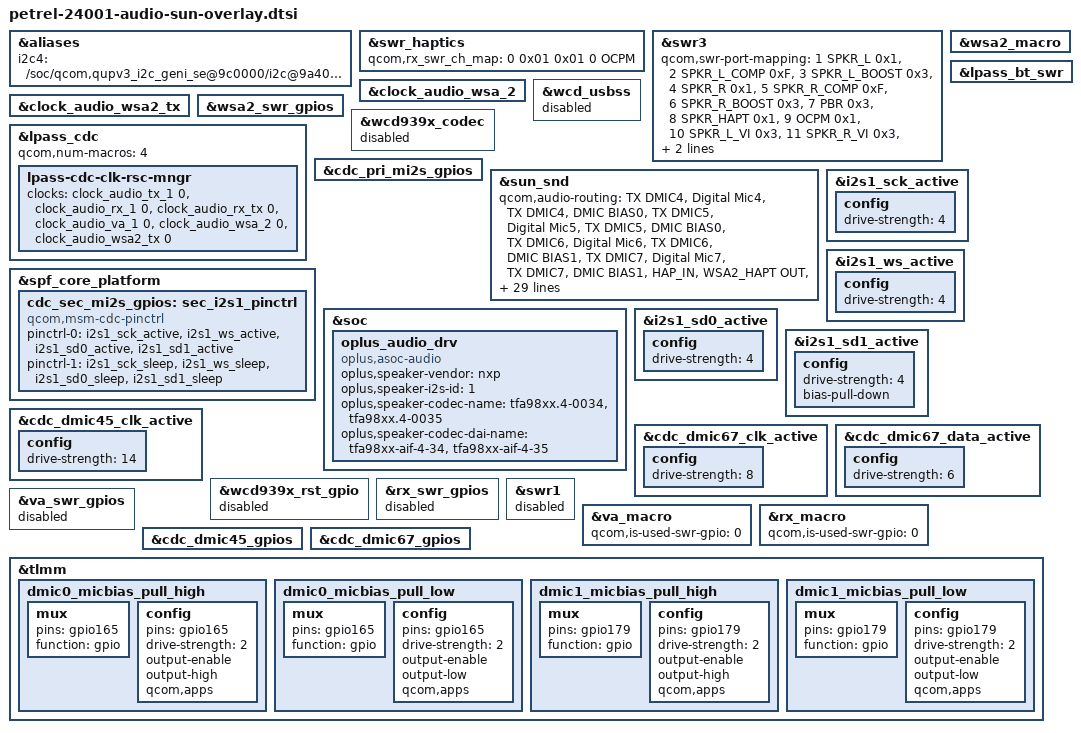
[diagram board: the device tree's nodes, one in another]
#include <dt-bindings/regulator/qcom,rpmh-regulator-levels.h>

&aliases {
	i2c4 = "/soc/qcom,qupv3_i2c_geni_se@9c0000/i2c@9a4000";
};

&swr_haptics {
	status = "ok";
	qcom,rx_swr_ch_map = <0 0x01 0x01 0 OCPM>;
};

&swr3 {
	qcom,swr-port-mapping = <1 SPKR_L 0x1>,
		<2 SPKR_L_COMP 0xF>, <3 SPKR_L_BOOST 0x3>,
		<4 SPKR_R 0x1>, <5 SPKR_R_COMP 0xF>,
		<6 SPKR_R_BOOST 0x3>, <7 PBR 0x3>,
		<8 SPKR_HAPT 0x1>, <9 OCPM 0x1>, // Change from <9 OCPM 0x3> to <9 OCPM 0x1>
		<10 SPKR_L_VI 0x3>, <11 SPKR_R_VI 0x3>,
		<12 SPKR_IPCM 0x3>, <13 CPS 0x3>;
};

&clock_audio_wsa_2 {
	status = "ok";
};

&clock_audio_wsa2_tx {
	status = "ok";
};

&wsa2_swr_gpios {
	status = "ok";
};

&swr3 {
	qcom,swr-num-dev = <1>; // only haptics connected
};

&wsa2_macro {
	status = "ok";
};

&lpass_cdc {
	qcom,num-macros = <4>;
	lpass-cdc-clk-rsc-mngr {
		clock-names = "tx_core_clk", "rx_core_clk", "rx_tx_core_clk", "va_core_clk",
		"wsa2_core_clk", "wsa2_tx_core_clk";
		clocks = <&clock_audio_tx_1 0>, <&clock_audio_rx_1 0>,
			<&clock_audio_rx_tx 0>, <&clock_audio_va_1 0>,
			<&clock_audio_wsa_2 0>, <&clock_audio_wsa2_tx 0>;
	};
};

&lpass_bt_swr {
	status = "ok";
};

&wcd_usbss {
	status = "disabled";
};

&wcd939x_codec {
	status = "disabled";
};

&cdc_pri_mi2s_gpios {
	status = "ok";
};

&sun_snd {
	qcom,audio-routing =
		"TX DMIC4", "Digital Mic4",
		"TX DMIC4", "DMIC BIAS0",
		"TX DMIC5", "Digital Mic5",
		"TX DMIC5", "DMIC BIAS0",
		"TX DMIC6", "Digital Mic6",
		"TX DMIC6", "DMIC BIAS1",
		"TX DMIC7", "Digital Mic7",
		"TX DMIC7", "DMIC BIAS1",
		"HAP_IN", "WSA2_HAPT OUT", // haptics connect to wsa2
		"RX_TX DEC0_INP", "TX DEC0 MUX",
		"RX_TX DEC1_INP", "TX DEC1 MUX",
		"RX_TX DEC2_INP", "TX DEC2 MUX",
		"RX_TX DEC3_INP", "TX DEC3 MUX",
		"VA SWR_INPUT", "VA_SWR_CLK",
		"VA_AIF1 CAP", "VA_SWR_CLK",
		"VA_AIF2 CAP", "VA_SWR_CLK",
		"VA_AIF3 CAP", "VA_SWR_CLK",
		"VA DMIC4", "Digital Mic4",
		"VA DMIC5", "Digital Mic5",
		"VA DMIC6", "Digital Mic6",
		"VA DMIC7", "Digital Mic7",
		"VA DMIC4", "DMIC BIAS0",
		"VA DMIC5", "DMIC BIAS0",
		"VA DMIC6", "DMIC BIAS1",
		"VA DMIC7", "DMIC BIAS1";

	qcom,mi2s-audio-intf = <1>;
	qcom,tdm-audio-intf = <0>;
	qcom,wcd-disabled = <1>;

	qcom,pri-mi2s-gpios = <&cdc_pri_mi2s_gpios>;
	qcom,sec-mi2s-gpios = <&cdc_sec_mi2s_gpios>;
	swr-haptics-unsupported; // disable qcom haptics
	oplus-swr-haptics-supported; // use oplus haptics
	qcom,wcn-bt = <1>;

	asoc-codec  = <&stub_codec>, <&lpass_cdc>, <&swr_haptics>;
	asoc-codec-names = "msm-stub-codec.1", "lpass-cdc",
						"swr-haptics";

	qcom,cdc-dmic67-gpios = <&cdc_dmic67_gpios>;

	pinctrl-names = "dmic0_micbias_pull_high", "dmic0_micbias_pull_low",
					"dmic1_micbias_pull_high", "dmic1_micbias_pull_low";
	pinctrl-0 = <&dmic0_micbias_pull_high>;
	pinctrl-1 = <&dmic0_micbias_pull_low>;
	pinctrl-2 = <&dmic1_micbias_pull_high>;
	pinctrl-3 = <&dmic1_micbias_pull_low>;

	oplus,dmic-regulator-config;
	oplus,dmic-micb-supply = <&BOB1>;
	oplus,dmic-micb-voltage = <3296000 3800000>;
};

&spf_core_platform {
	cdc_sec_mi2s_gpios: sec_i2s1_pinctrl {
		status = "ok";
		compatible = "qcom,msm-cdc-pinctrl";
		pinctrl-names = "aud_active", "aud_sleep";
		pinctrl-0 = <&i2s1_sck_active &i2s1_ws_active
				&i2s1_sd0_active &i2s1_sd1_active>;
		pinctrl-1 = <&i2s1_sck_sleep &i2s1_ws_sleep
				&i2s1_sd0_sleep &i2s1_sd1_sleep>;
		#gpio-cells = <0>;
	};
};

&soc {
	oplus_audio_drv: oplus_audio_drv {
		compatible = "oplus,asoc-audio";
		//for nxp speaker
		oplus,speaker-vendor = "nxp";
		oplus,speaker-i2s-id = <1>;
		oplus,speaker-codec-name = "tfa98xx.4-0034", "tfa98xx.4-0035";
		oplus,speaker-codec-dai-name = "tfa98xx-aif-4-34", "tfa98xx-aif-4-35";
	};
};

&i2s1_sck_active {
	config {
		drive-strength = <4>;   /* 4 mA */
	};
};

&i2s1_ws_active {
	config {
		drive-strength = <4>;   /* 4 mA */
	};
};

&i2s1_sd0_active {
	config {
		drive-strength = <4>;   /* 4 mA */
	};
};

&i2s1_sd1_active {
	config {
		drive-strength = <4>;   /* 4 mA */
		bias-pull-down;         /* PULL DOWN */
	};
};

&cdc_dmic45_clk_active {
	config {
		drive-strength = <14>;   /* 14 mA */
	};
};

&cdc_dmic67_clk_active {
	config {
		drive-strength = <8>;   /* 8 mA */
	};
};

&cdc_dmic67_data_active {
	config {
		drive-strength = <6>;   /* 6 mA */
	};
};

&wcd939x_rst_gpio {
	status = "disabled";
};

&rx_swr_gpios {
	status = "disabled";
};

&va_swr_gpios {
	status = "disabled";
};

&swr1 {
	status = "disabled";
};

&va_macro {
	qcom,is-used-swr-gpio = <0>;
	/delete-property/ qcom,va-swr-gpios;
};

&rx_macro {
	qcom,is-used-swr-gpio = <0>;
	/delete-property/ qcom,rx-swr-gpios;
};

&cdc_dmic45_gpios {
	status = "ok";
};

&cdc_dmic67_gpios {
	status = "ok";
};

&tlmm{
	dmic0_micbias_pull_high: dmic0_micbias_pull_high {
		mux {
			pins = "gpio165";
			function = "gpio";
		};

		config {
			pins = "gpio165";
			drive-strength = <2>;
			output-enable;
			output-high;
			qcom,apps;
		};
	};

	dmic0_micbias_pull_low: dmic0_micbias_pull_low {
		mux {
			pins = "gpio165";
			function = "gpio";
		};

		config {
			pins = "gpio165";
			drive-strength = <2>;
			output-enable;
			output-low;
			qcom,apps;
		};
	};

	dmic1_micbias_pull_high: dmic1_micbias_pull_high {
		mux {
			pins = "gpio179";
			function = "gpio";
		};

		config {
			pins = "gpio179";
			drive-strength = <2>;
			output-enable;
			output-high;
			qcom,apps;
		};
	};

	dmic1_micbias_pull_low: dmic1_micbias_pull_low {
		mux {
			pins = "gpio179";
			function = "gpio";
		};

		config {
			pins = "gpio179";
			drive-strength = <2>;
			output-enable;
			output-low;
			qcom,apps;
		};
	};
};
